# EFM32TG11B520F128GQ48 register map
File version: 5.8.2
CPU: CM0PLUS r0p1, little endian, MPU, no FPU, 3 interrupt priority bits
Registers are 32-bit, read-write, reset 0x0 unless marked. A register's access mark holds for its fields unless they carry their own. Offsets are from the block's base; [hi:lo] are bit positions; {n}, {i} and the like mark numbered series; 'fields as' and 'values as' point back to an identical list.

## EMU
Base 0x400E3000
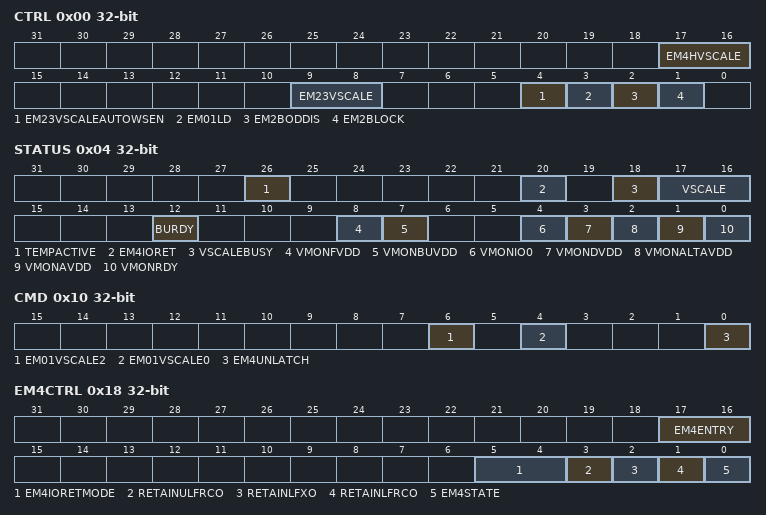
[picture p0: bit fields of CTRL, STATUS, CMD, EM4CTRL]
0x00 CTRL — Control Register
  [17:16] EM4HVSCALE — EM4H Voltage Scale
    0=VSCALE2 (Voltage Scale Level 2); 2=VSCALE0 (Voltage Scale Level 0)
  [9:8] EM23VSCALE — EM23 Voltage Scale
    values as EM4HVSCALE
  [4] EM23VSCALEAUTOWSEN — Automatically Configures Flash and Frequency to Wakeup From EM2 or EM3 at Low Voltage
  [3] EM01LD — Reserved for internal use. Do not change.
  [2] EM2BODDIS — Disable BOD in EM2
  [1] EM2BLOCK — Energy Mode 2 Block
0x04 STATUS ro
  [26] TEMPACTIVE — Temperature Measurement Active
  [20] EM4IORET — IO Retention Status
  [18] VSCALEBUSY — System is Busy Scaling Voltage
  [17:16] VSCALE — Current Voltage Scale Value
    0=Voltage Scale Level 2; 2=Voltage Scale Level 0
  [12] BURDY — Backup Mode Ready
  [8] VMONFVDD — VMON VDDFLASH Channel
  [7] VMONBUVDD — VMON BUVDD Channel
  [4] VMONIO0 — VMON IOVDD0 Channel
  [3] VMONDVDD — VMON DVDD Channel
  [2] VMONALTAVDD — Alternate VMON AVDD Channel
  [1] VMONAVDD — VMON AVDD Channel
  [0] VMONRDY — VMON Ready
0x08 LOCK — Configuration Lock Register
  [15:0] LOCKKEY — Configuration Lock Key
    0=UNLOCKED; 1=LOCKED
0x0C RAM0CTRL — Memory Control Register
  [2:0] RAMPOWERDOWN — RAM0 Blockset Power-down
    0=NONE (None of the RAM blocks powered down); 4=BLK3 (Power down RAM block 3); 6=BLK2TO3 (Power down RAM blocks 2 and above); 7=BLK1TO3 (Power down RAM blocks 1 and above)
0x10 CMD wo — Command Register
  [6] EM01VSCALE2 — EM01 Voltage Scale Command to Scale to Voltage Scale Level 2
  [4] EM01VSCALE0 — EM01 Voltage Scale Command to Scale to Voltage Scale Level 0
  [0] EM4UNLATCH
0x18 EM4CTRL — EM4 Control Register
  [17:16] EM4ENTRY wo — Energy Mode 4 Entry
  [5:4] EM4IORETMODE — EM4 IO Retention Disable
    0=DISABLE (No Retention: Pads enter reset state when entering EM4); 1=EM4EXIT (Retention through EM4: Pads enter reset state when exiting EM4); 2=SWUNLATCH (Retention through EM4 and Wakeup: software writes UNLATCH register to remove retention)
  [3] RETAINULFRCO — ULFRCO Retain During EM4S
  [2] RETAINLFXO — LFXO Retain During EM4
  [1] RETAINLFRCO — LFRCO Retain During EM4
  [0] EM4STATE — Energy Mode 4 State
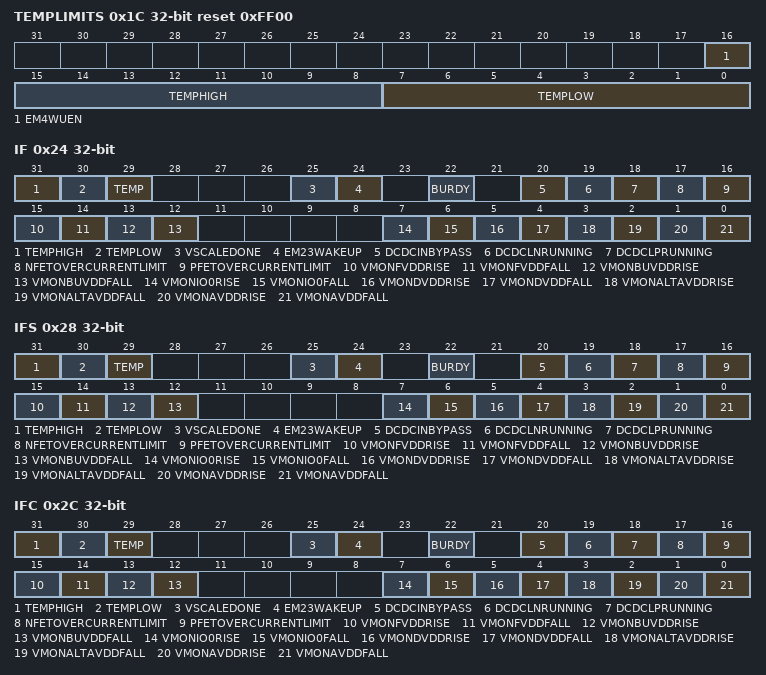
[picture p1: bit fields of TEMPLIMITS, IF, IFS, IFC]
0x1C TEMPLIMITS reset 0xFF00 — Temperature Limits for Interrupt Generation
  [16] EM4WUEN — Enable EM4 Wakeup Due to Low/high Temperature
  [15:8] TEMPHIGH — Temperature High Limit
  [7:0] TEMPLOW — Temperature Low Limit
0x20 TEMP ro — Value of Last Temperature Measurement
  [7:0] TEMP — Temperature Measurement
0x24 IF ro — Interrupt Flag Register
  [31] TEMPHIGH — Temperature High Limit Reached
  [30] TEMPLOW — Temperature Low Limit Reached
  [29] TEMP — New Temperature Measurement Valid
  [25] VSCALEDONE — Voltage Scale Steps Done IRQ
  [24] EM23WAKEUP — Wakeup IRQ From EM2 and EM3
  [22] BURDY — Backup Functionality Ready Interrupt Flag
  [20] DCDCINBYPASS — DCDC is in Bypass
  [19] DCDCLNRUNNING — LN Mode is Running
  [18] DCDCLPRUNNING — LP Mode is Running
  [17] NFETOVERCURRENTLIMIT — NFET Current Limit Hit
  [16] PFETOVERCURRENTLIMIT — PFET Current Limit Hit
  [15] VMONFVDDRISE — VMON VDDFLASH Channel Rise
  [14] VMONFVDDFALL — VMON VDDFLASH Channel Fall
  [13] VMONBUVDDRISE — VMON BUVDD Channel Rise
  [12] VMONBUVDDFALL — VMON BACKUP Channel Fall
  [7] VMONIO0RISE — VMON IOVDD0 Channel Rise
  [6] VMONIO0FALL — VMON IOVDD0 Channel Fall
  [5] VMONDVDDRISE — VMON DVDD Channel Rise
  [4] VMONDVDDFALL — VMON DVDD Channel Fall
  [3] VMONALTAVDDRISE — Alternate VMON AVDD Channel Rise
  [2] VMONALTAVDDFALL — Alternate VMON AVDD Channel Fall
  [1] VMONAVDDRISE — VMON AVDD Channel Rise
  [0] VMONAVDDFALL — VMON AVDD Channel Fall
0x28 IFS wo — Interrupt Flag Set Register
  [31] TEMPHIGH — Set TEMPHIGH Interrupt Flag
  [30] TEMPLOW — Set TEMPLOW Interrupt Flag
  [29] TEMP — Set TEMP Interrupt Flag
  [25] VSCALEDONE — Set VSCALEDONE Interrupt Flag
  [24] EM23WAKEUP — Set EM23WAKEUP Interrupt Flag
  [22] BURDY — Set BURDY Interrupt Flag
  [20] DCDCINBYPASS — Set DCDCINBYPASS Interrupt Flag
  [19] DCDCLNRUNNING — Set DCDCLNRUNNING Interrupt Flag
  [18] DCDCLPRUNNING — Set DCDCLPRUNNING Interrupt Flag
  [17] NFETOVERCURRENTLIMIT — Set NFETOVERCURRENTLIMIT Interrupt Flag
  [16] PFETOVERCURRENTLIMIT — Set PFETOVERCURRENTLIMIT Interrupt Flag
  [15] VMONFVDDRISE — Set VMONFVDDRISE Interrupt Flag
  [14] VMONFVDDFALL — Set VMONFVDDFALL Interrupt Flag
  [13] VMONBUVDDRISE — Set VMONBUVDDRISE Interrupt Flag
  [12] VMONBUVDDFALL — Set VMONBUVDDFALL Interrupt Flag
  [7] VMONIO0RISE — Set VMONIO0RISE Interrupt Flag
  [6] VMONIO0FALL — Set VMONIO0FALL Interrupt Flag
  [5] VMONDVDDRISE — Set VMONDVDDRISE Interrupt Flag
  [4] VMONDVDDFALL — Set VMONDVDDFALL Interrupt Flag
  [3] VMONALTAVDDRISE — Set VMONALTAVDDRISE Interrupt Flag
  [2] VMONALTAVDDFALL — Set VMONALTAVDDFALL Interrupt Flag
  [1] VMONAVDDRISE — Set VMONAVDDRISE Interrupt Flag
  [0] VMONAVDDFALL — Set VMONAVDDFALL Interrupt Flag
0x2C IFC wo — Interrupt Flag Clear Register
  [31] TEMPHIGH — Clear TEMPHIGH Interrupt Flag
  [30] TEMPLOW — Clear TEMPLOW Interrupt Flag
  [29] TEMP — Clear TEMP Interrupt Flag
  [25] VSCALEDONE — Clear VSCALEDONE Interrupt Flag
  [24] EM23WAKEUP — Clear EM23WAKEUP Interrupt Flag
  [22] BURDY — Clear BURDY Interrupt Flag
  [20] DCDCINBYPASS — Clear DCDCINBYPASS Interrupt Flag
  [19] DCDCLNRUNNING — Clear DCDCLNRUNNING Interrupt Flag
  [18] DCDCLPRUNNING — Clear DCDCLPRUNNING Interrupt Flag
  [17] NFETOVERCURRENTLIMIT — Clear NFETOVERCURRENTLIMIT Interrupt Flag
  [16] PFETOVERCURRENTLIMIT — Clear PFETOVERCURRENTLIMIT Interrupt Flag
  [15] VMONFVDDRISE — Clear VMONFVDDRISE Interrupt Flag
  [14] VMONFVDDFALL — Clear VMONFVDDFALL Interrupt Flag
  [13] VMONBUVDDRISE — Clear VMONBUVDDRISE Interrupt Flag
  [12] VMONBUVDDFALL — Clear VMONBUVDDFALL Interrupt Flag
  [7] VMONIO0RISE — Clear VMONIO0RISE Interrupt Flag
  [6] VMONIO0FALL — Clear VMONIO0FALL Interrupt Flag
  [5] VMONDVDDRISE — Clear VMONDVDDRISE Interrupt Flag
  [4] VMONDVDDFALL — Clear VMONDVDDFALL Interrupt Flag
  [3] VMONALTAVDDRISE — Clear VMONALTAVDDRISE Interrupt Flag
  [2] VMONALTAVDDFALL — Clear VMONALTAVDDFALL Interrupt Flag
  [1] VMONAVDDRISE — Clear VMONAVDDRISE Interrupt Flag
  [0] VMONAVDDFALL — Clear VMONAVDDFALL Interrupt Flag
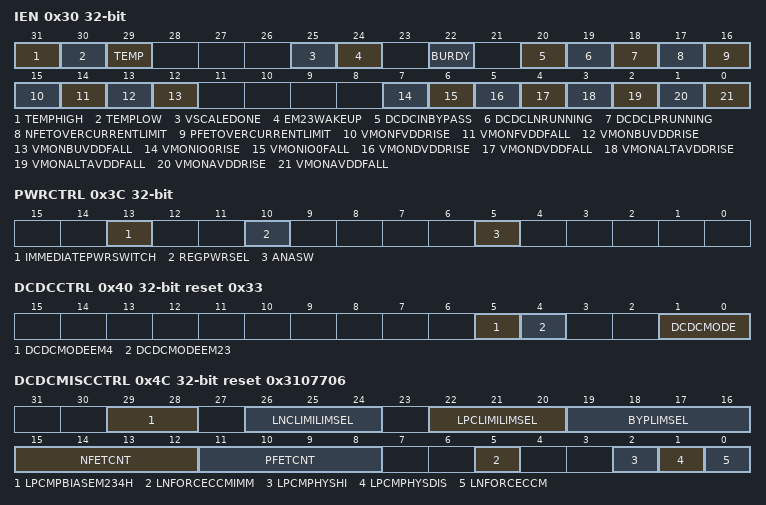
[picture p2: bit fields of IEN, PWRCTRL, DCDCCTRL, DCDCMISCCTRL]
0x30 IEN — Interrupt Enable Register
  [31] TEMPHIGH — TEMPHIGH Interrupt Enable
  [30] TEMPLOW — TEMPLOW Interrupt Enable
  [29] TEMP — TEMP Interrupt Enable
  [25] VSCALEDONE — VSCALEDONE Interrupt Enable
  [24] EM23WAKEUP — EM23WAKEUP Interrupt Enable
  [22] BURDY — BURDY Interrupt Enable
  [20] DCDCINBYPASS — DCDCINBYPASS Interrupt Enable
  [19] DCDCLNRUNNING — DCDCLNRUNNING Interrupt Enable
  [18] DCDCLPRUNNING — DCDCLPRUNNING Interrupt Enable
  [17] NFETOVERCURRENTLIMIT — NFETOVERCURRENTLIMIT Interrupt Enable
  [16] PFETOVERCURRENTLIMIT — PFETOVERCURRENTLIMIT Interrupt Enable
  [15] VMONFVDDRISE — VMONFVDDRISE Interrupt Enable
  [14] VMONFVDDFALL — VMONFVDDFALL Interrupt Enable
  [13] VMONBUVDDRISE — VMONBUVDDRISE Interrupt Enable
  [12] VMONBUVDDFALL — VMONBUVDDFALL Interrupt Enable
  [7] VMONIO0RISE — VMONIO0RISE Interrupt Enable
  [6] VMONIO0FALL — VMONIO0FALL Interrupt Enable
  [5] VMONDVDDRISE — VMONDVDDRISE Interrupt Enable
  [4] VMONDVDDFALL — VMONDVDDFALL Interrupt Enable
  [3] VMONALTAVDDRISE — VMONALTAVDDRISE Interrupt Enable
  [2] VMONALTAVDDFALL — VMONALTAVDDFALL Interrupt Enable
  [1] VMONAVDDRISE — VMONAVDDRISE Interrupt Enable
  [0] VMONAVDDFALL — VMONAVDDFALL Interrupt Enable
0x34 PWRLOCK — Regulator and Supply Lock Register
  [15:0] LOCKKEY — Regulator and Supply Configuration Lock Key
    0=UNLOCKED; 1=LOCKED
0x3C PWRCTRL — Power Control Register
  [13] IMMEDIATEPWRSWITCH — Allows Immediate Switching of ANASW and REGPWRSEL Bitfields
  [10] REGPWRSEL — This Field Selects the Input Supply Pin for the Digital LDO
  [5] ANASW — Analog Switch Selection
0x40 DCDCCTRL reset 0x33 — DCDC Control
  [5] DCDCMODEEM4 — DCDC Mode EM4H
  [4] DCDCMODEEM23
  [1:0] DCDCMODE — Regulator Mode
    0=BYPASS (DCDC regulator is operating in bypass mode. Prior to configuring DCDCMODE=BYPASS, software must set EMU_DCDCCLIMCTRL.BYPLIMEN=1 to prevent excessive current between VREGVDD and DVDD supplies.); 1=LOWNOISE (DCDC regulator is operating in low noise mode.); 2=LOWPOWER (DCDC regulator is operating in low power mode.); 3=OFF (DCDC regulator is off and the bypass switch is off. Note: DVDD must be supplied externally)
0x4C DCDCMISCCTRL reset 0x3107706 — DCDC Miscellaneous Control Register
  [29:28] LPCMPBIASEM234H — LP Mode Comparator Bias Selection for EM23 or EM4H
    0=BIAS0 (Maximum load current less than 75uA.); 1=BIAS1 (Maximum load current less than 500uA.); 2=BIAS2 (Maximum load current less than 2.5mA.); 3=BIAS3 (Maximum load current less than 10mA.)
  [26:24] LNCLIMILIMSEL — Current Limit Level Selection for Current Limiter in LN Mode
  [22:20] LPCLIMILIMSEL — Current Limit Level Selection for Current Limiter in LP Mode
  [19:16] BYPLIMSEL — Current Limit in Bypass Mode
  [15:12] NFETCNT — NFET Switch Number Selection
  [11:8] PFETCNT — PFET Switch Number Selection
  [5] LNFORCECCMIMM — Force DCDC Into CCM Mode Immediately, Based on LNFORCECCM
  [2] LPCMPHYSHI — Comparator Threshold on the High Side
  [1] LPCMPHYSDIS — Disable LP Mode Hysteresis in the State Machine Control
  [0] LNFORCECCM — Force DCDC Into CCM Mode in Low Noise Operation
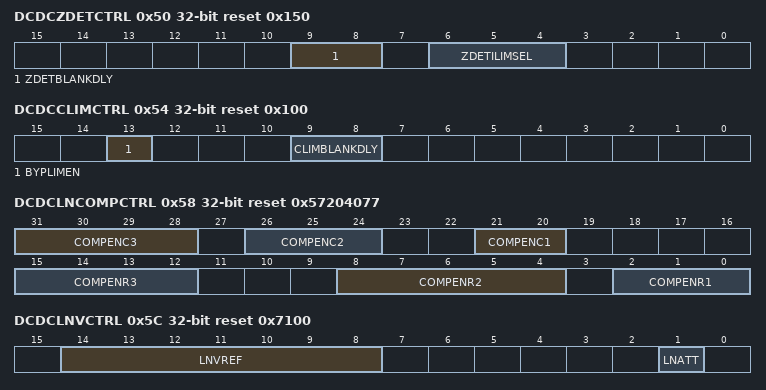
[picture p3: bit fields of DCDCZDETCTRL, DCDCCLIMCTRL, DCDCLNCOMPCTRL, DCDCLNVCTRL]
0x50 DCDCZDETCTRL reset 0x150 — DCDC Power Train NFET Zero Current Detector Control Register
  [9:8] ZDETBLANKDLY — Reserved for internal use. Do not change.
  [6:4] ZDETILIMSEL — Reverse Current Limit Level Selection for Zero Detector
0x54 DCDCCLIMCTRL reset 0x100 — DCDC Power Train PFET Current Limiter Control Register
  [13] BYPLIMEN — Bypass Current Limit Enable
  [9:8] CLIMBLANKDLY — Reserved for internal use. Do not change.
0x58 DCDCLNCOMPCTRL reset 0x57204077 — DCDC Low Noise Compensator Control Register
  [31:28] COMPENC3 — Low Noise Mode Compensator C3 Trim Value
  [26:24] COMPENC2 — Low Noise Mode Compensator C2 Trim Value
  [21:20] COMPENC1 — Low Noise Mode Compensator C1 Trim Value
  [15:12] COMPENR3 — Low Noise Mode Compensator R3 Trim Value
  [8:4] COMPENR2 — Low Noise Mode Compensator R2 Trim Value
  [2:0] COMPENR1 — Low Noise Mode Compensator R1 Trim Value
0x5C DCDCLNVCTRL reset 0x7100 — DCDC Low Noise Voltage Register
  [14:8] LNVREF — Low Noise Mode VREF Trim
  [1] LNATT — Low Noise Mode Feedback Attenuation
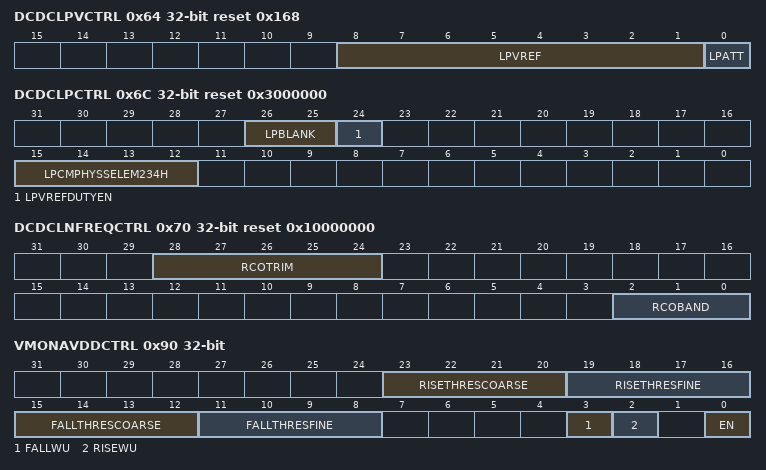
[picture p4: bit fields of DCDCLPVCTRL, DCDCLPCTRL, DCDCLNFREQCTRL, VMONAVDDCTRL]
0x64 DCDCLPVCTRL reset 0x168 — DCDC Low Power Voltage Register
  [8:1] LPVREF — LP Mode Reference Selection for EM23 and EM4H
  [0] LPATT — Low Power Feedback Attenuation
0x6C DCDCLPCTRL reset 0x3000000 — DCDC Low Power Control Register
  [26:25] LPBLANK — Reserved for internal use. Do not change.
  [24] LPVREFDUTYEN — LP Mode Duty Cycling Enable
  [15:12] LPCMPHYSSELEM234H — LP Mode Hysteresis Selection for EM23 and EM4H
0x70 DCDCLNFREQCTRL reset 0x10000000 — DCDC Low Noise Controller Frequency Control
  [28:24] RCOTRIM — Reserved for internal use. Do not change.
  [2:0] RCOBAND — LN Mode RCO Frequency Band Selection
0x78 DCDCSYNC ro — DCDC Read Status Register
  [0] DCDCCTRLBUSY — DCDC CTRL Register Transfer Busy
0x90 VMONAVDDCTRL — VMON AVDD Channel Control
  [23:20] RISETHRESCOARSE — Rising Threshold Coarse Adjust
  [19:16] RISETHRESFINE — Rising Threshold Fine Adjust
  [15:12] FALLTHRESCOARSE — Falling Threshold Coarse Adjust
  [11:8] FALLTHRESFINE — Falling Threshold Fine Adjust
  [3] FALLWU — Fall Wakeup
  [2] RISEWU — Rise Wakeup
  [0] EN — Enable
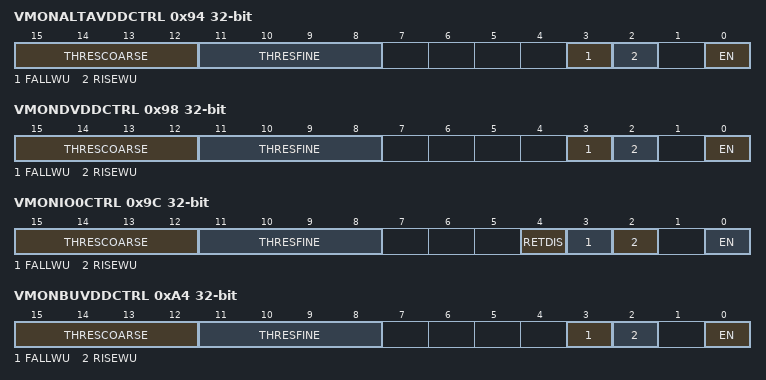
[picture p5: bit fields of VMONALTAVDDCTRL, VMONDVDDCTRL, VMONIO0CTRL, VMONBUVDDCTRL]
0x94 VMONALTAVDDCTRL — Alternate VMON AVDD Channel Control
  [15:12] THRESCOARSE — Threshold Coarse Adjust
  [11:8] THRESFINE — Threshold Fine Adjust
  [3] FALLWU — Fall Wakeup
  [2] RISEWU — Rise Wakeup
  [0] EN — Enable
0x98 VMONDVDDCTRL — VMON DVDD Channel Control
  fields as VMONALTAVDDCTRL
0x9C VMONIO0CTRL — VMON IOVDD0 Channel Control
  [15:12] THRESCOARSE — Threshold Coarse Adjust
  [11:8] THRESFINE — Threshold Fine Adjust
  [4] RETDIS — EM4 IO0 Retention Disable
  [3] FALLWU — Fall Wakeup
  [2] RISEWU — Rise Wakeup
  [0] EN — Enable
0xA4 VMONBUVDDCTRL — VMON BUVDD Channel Control
  fields as VMONALTAVDDCTRL
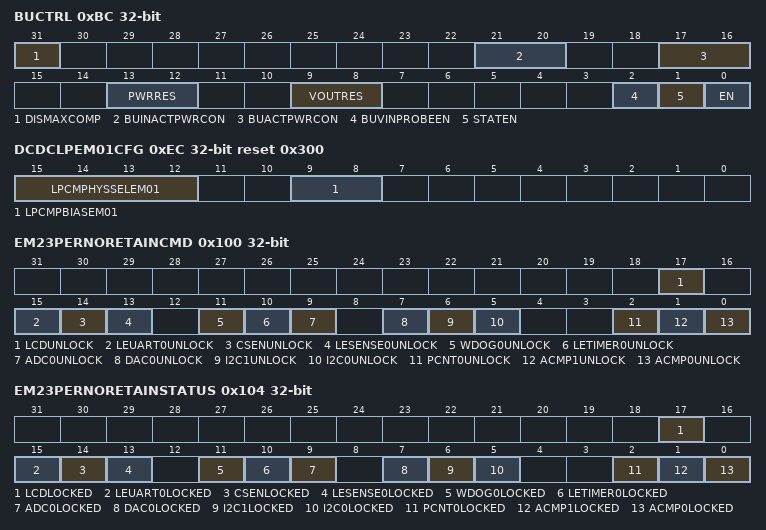
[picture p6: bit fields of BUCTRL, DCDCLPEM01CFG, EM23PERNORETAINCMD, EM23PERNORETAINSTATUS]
0xBC BUCTRL — Backup Power Configuration Register
  [31] DISMAXCOMP — Disable MAIN-BU Comparator
  [21:20] BUINACTPWRCON — Power Connection Configuration When Not in Backup Mode
    0=NONE (No connection.); 1=MAINBU (Main power and backup power are connected through a diode, allowing current to flow from main power source to backup power source, but not the other way.); 2=BUMAIN (Main power and backup power are connected through a diode, allowing current to flow from backup power source to main power source, but not the other way.); 3=NODIODE (Main power and backup power are connected without diode.)
  [17:16] BUACTPWRCON — Power Connection Configuration in Backup Mode
    0=NONE (No connection.); 1=MAINBU (Main power and backup power are connected through a diode, allowing current to flow from backup power source to main power source, but not the other way.); 2=BUMAIN (Main power and backup power are connected through a diode, allowing current to flow from main power source to backup power source, but not the other way.); 3=NODIODE (Main power and backup power are connected without diode.)
  [13:12] PWRRES — Power Domain Resistor Select
    {v}=RES{v} (Main power and backup power connected with RES{v} series resistance.) (v=0..3)
  [9:8] VOUTRES — BU_VOUT Resistor Select
    0=DIS (BU_VOUT is not connected); 1=WEAK (Enable weak switch between BU_VOUT and backup domain power supply.); 2=MED (Enable medium switch between BU_VOUT and backup domain power supply.); 3=STRONG (Enable strong switch between BU_VOUT and backup domain power supply.)
  [2] BUVINPROBEEN — Enable BU_VIN Probing
  [1] STATEN — Enable Backup Mode Status Export
  [0] EN — Enable Backup Mode
0xEC DCDCLPEM01CFG reset 0x300 — Configuration Bits for Low Power Mode to Be Applied During EM01, This Field is Only Relevant If LP Mode is Used in EM01
  [15:12] LPCMPHYSSELEM01 — LP Mode Hysteresis Selection for EM01
  [9:8] LPCMPBIASEM01 — LP Mode Comparator Bias Selection for EM01
    values as DCDCMISCCTRL.LPCMPBIASEM234H
0x100 EM23PERNORETAINCMD wo — Clears Corresponding Bits in EM23PERNORETAINSTATUS Unlocking Access to Peripheral
  [17] LCDUNLOCK — Clears Status Bit of LCD and Unlocks Access to It
  [15] LEUART0UNLOCK — Clears Status Bit of LEUART0 and Unlocks Access to It
  [14] CSENUNLOCK — Clears Status Bit of CSEN and Unlocks Access to It
  [13] LESENSE0UNLOCK — Clears Status Bit of LESENSE0 and Unlocks Access to It
  [11] WDOG0UNLOCK — Clears Status Bit of WDOG0 and Unlocks Access to It
  [10] LETIMER0UNLOCK — Clears Status Bit of LETIMER0 and Unlocks Access to It
  [9] ADC0UNLOCK — Clears Status Bit of ADC0 and Unlocks Access to It
  [7] DAC0UNLOCK — Clears Status Bit of DAC0 and Unlocks Access to It
  [6] I2C1UNLOCK — Clears Status Bit of I2C1 and Unlocks Access to It
  [5] I2C0UNLOCK — Clears Status Bit of I2C0 and Unlocks Access to It
  [2] PCNT0UNLOCK — Clears Status Bit of PCNT0 and Unlocks Access to It
  [1] ACMP1UNLOCK — Clears Status Bit of ACMP1 and Unlocks Access to It
  [0] ACMP0UNLOCK — Clears Status Bit of ACMP0 and Unlocks Access to It
0x104 EM23PERNORETAINSTATUS ro — Status Indicating If Peripherals Were Powered Down in EM23, Subsequently Locking Access to It
  [17] LCDLOCKED — Indicates If LCD Powered Down During EM23
  [15] LEUART0LOCKED — Indicates If LEUART0 Powered Down During EM23
  [14] CSENLOCKED — Indicates If CSEN Powered Down During EM23
  [13] LESENSE0LOCKED — Indicates If LESENSE0 Powered Down During EM23
  [11] WDOG0LOCKED — Indicates If WDOG0 Powered Down During EM23
  [10] LETIMER0LOCKED — Indicates If LETIMER0 Powered Down During EM23
  [9] ADC0LOCKED — Indicates If ADC0 Powered Down During EM23
  [7] DAC0LOCKED — Indicates If DAC0 Powered Down During EM23
  [6] I2C1LOCKED — Indicates If I2C1 Powered Down During EM23
  [5] I2C0LOCKED — Indicates If I2C0 Powered Down During EM23
  [2] PCNT0LOCKED — Indicates If PCNT0 Powered Down During EM23
  [1] ACMP1LOCKED — Indicates If ACMP1 Powered Down During EM23
  [0] ACMP0LOCKED — Indicates If ACMP0 Powered Down During EM23
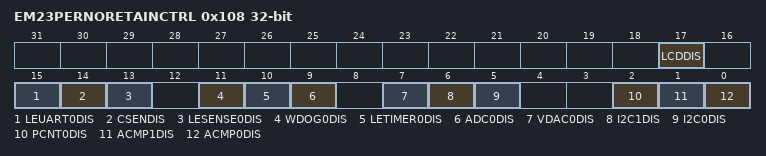
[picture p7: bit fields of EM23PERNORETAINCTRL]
0x108 EM23PERNORETAINCTRL — When Set Corresponding Peripherals May Get Powered Down in EM23
  [17] LCDDIS — Allow Power Down of LCD During EM23
  [15] LEUART0DIS — Allow Power Down of LEUART0 During EM23
  [14] CSENDIS — Allow Power Down of CSEN During EM23
  [13] LESENSE0DIS — Allow Power Down of LESENSE0 During EM23
  [11] WDOG0DIS — Allow Power Down of WDOG0 During EM23
  [10] LETIMER0DIS — Allow Power Down of LETIMER0 During EM23
  [9] ADC0DIS — Allow Power Down of ADC0 During EM23
  [7] VDAC0DIS — Allow Power Down of DAC0 During EM23
  [6] I2C1DIS — Allow Power Down of I2C1 During EM23
  [5] I2C0DIS — Allow Power Down of I2C0 During EM23
  [2] PCNT0DIS — Allow Power Down of PCNT0 During EM23
  [1] ACMP1DIS — Allow Power Down of ACMP1 During EM23
  [0] ACMP0DIS — Allow Power Down of ACMP0 During EM23

## Notices in the file
# License
Copyright 2019 Silicon Laboratories Inc. www.silabs.com
SPDX-License-Identifier: Zlib
The licensor of this software is Silicon Laboratories Inc.
This software is provided 'as-is', without any express or implied
warranty. In no event will the authors be held liable for any damages
arising from the use of this software.
Permission is granted to anyone to use this software for any purpose,
including commercial applications, and to alter it and redistribute it
freely, subject to the following restrictions:
1. The origin of this software must not be misrepresented; you must not
claim that you wrote the original software. If you use this software
in a product, an acknowledgment in the product documentation would be
appreciated but is not required.
2. Altered source versions must be plainly marked as such, and must not be
misrepresented as being the original software.
3. This notice may not be removed or altered from any source distribution.
